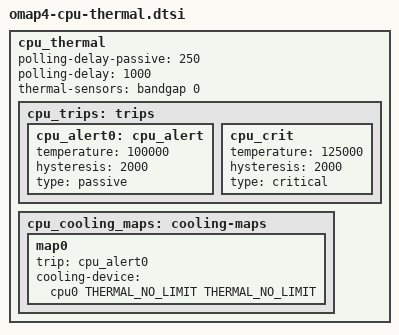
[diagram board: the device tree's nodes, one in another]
#include <dt-bindings/thermal/thermal.h>
cpu_thermal: cpu_thermal {
	polling-delay-passive = <250>;  
	polling-delay = <1000>;  
	thermal-sensors = <&bandgap     0>;
	cpu_trips: trips {
		cpu_alert0: cpu_alert {
			temperature = <100000>;  
			hysteresis = <2000>;  
			type = "passive";
		};
		cpu_crit: cpu_crit {
			temperature = <125000>;  
			hysteresis = <2000>;  
			type = "critical";
		};
	};
	cpu_cooling_maps: cooling-maps {
		map0 {
			trip = <&cpu_alert0>;
			cooling-device =
				<&cpu0 THERMAL_NO_LIMIT THERMAL_NO_LIMIT>;
		};
	};
};
